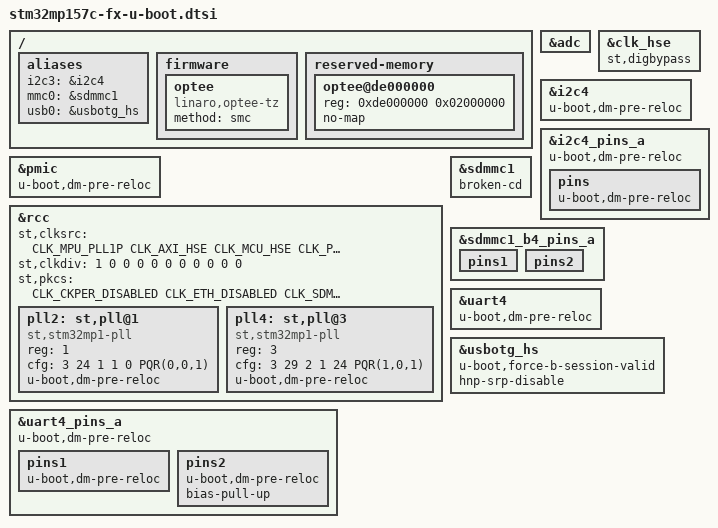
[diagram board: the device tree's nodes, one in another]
// SPDX-License-Identifier: GPL-2.0+ OR BSD-3-Clause
/*
 * Copyright : STMicroelectronics 2018
 */

#include <dt-bindings/clock/stm32mp1-clksrc.h>
#include "stm32mp15fx-u-boot.dtsi"
#include "stm32mp15-ddr3-1x4Gb-800.dtsi"

/ {
	aliases {
		i2c3 = &i2c4;
		mmc0 = &sdmmc1;
		usb0 = &usbotg_hs;
	};

	firmware {
		optee {
			compatible = "linaro,optee-tz";
			method = "smc";
		};
	};

	reserved-memory {
		optee@de000000 {
			reg = <0xde000000 0x02000000>;
			no-map;
		};
	};
};

&adc {
	status = "okay";
};

&clk_hse {
	st,digbypass;
};

&i2c4 {
	u-boot,dm-pre-reloc;
};

&i2c4_pins_a {
	u-boot,dm-pre-reloc;
	pins {
		u-boot,dm-pre-reloc;
	};
};

&pmic {
	u-boot,dm-pre-reloc;
};

&rcc {
	st,clksrc = <
		CLK_MPU_PLL1P
		CLK_AXI_HSE
		CLK_MCU_HSE
		CLK_PLL12_HSE
		CLK_PLL3_HSE
		CLK_PLL4_HSE
		CLK_RTC_LSE
		CLK_MCO1_DISABLED
		CLK_MCO2_DISABLED
	>;

	st,clkdiv = <
		1 /*MPU*/
		0 /*AXI*/
		0 /*MCU*/
		0 /*APB1*/
		0 /*APB2*/
		0 /*APB3*/
		0 /*APB4*/
		0 /*APB5*/
		0 /*RTC*/
		0 /*MCO1*/
		0 /*MCO2*/
	>;

	st,pkcs = <
		CLK_CKPER_DISABLED
		CLK_ETH_DISABLED
		CLK_SDMMC12_HCLK6
		CLK_STGEN_HSE
		CLK_USBPHY_PLL4R
		CLK_SPI2S1_PLL4P
		CLK_SPI2S23_DISABLED
		CLK_SPI45_DISABLED
		CLK_SPI6_DISABLED
		CLK_I2C46_PCLK5
		CLK_SDMMC3_DISABLED
		CLK_USBO_PLL4R
		CLK_ADC_PLL4R
		CLK_CEC_DISABLED
		CLK_I2C12_PCLK1
		CLK_I2C35_PCLK1
		CLK_UART1_PCLK5
		CLK_UART24_PCLK1
		CLK_UART35_PCLK1
		CLK_UART6_PCLK2
		CLK_UART78_PCLK1
		CLK_SPDIF_DISABLED
		CLK_SAI1_DISABLED
		CLK_SAI2_DISABLED
		CLK_SAI3_DISABLED
		CLK_SAI4_DISABLED
		CLK_RNG1_LSI
		CLK_RNG2_LSI
		CLK_LPTIM1_DISABLED
		CLK_LPTIM23_DISABLED
		CLK_LPTIM45_DISABLED
	>;

	pll2: st,pll@1 {
		compatible = "st,stm32mp1-pll";
		reg = <1>;
		cfg = < 3 24 1 1 0 PQR(0,0,1) >;
		u-boot,dm-pre-reloc;
	};

	pll4: st,pll@3 {
		compatible = "st,stm32mp1-pll";
		reg = <3>;
		cfg = < 3 29 2 1 24 PQR(1,0,1) >;
		u-boot,dm-pre-reloc;
	};
};

&sdmmc1 {
	u-boot,dm-spl;
	broken-cd;
	/delete-property/ cd-gpios;
};

&sdmmc1_b4_pins_a {
	u-boot,dm-spl;
	pins1 {
		u-boot,dm-spl;
	};
	pins2 {
		u-boot,dm-spl;
	};
};

&uart4 {
	u-boot,dm-pre-reloc;
};

&uart4_pins_a {
	u-boot,dm-pre-reloc;
	pins1 {
		u-boot,dm-pre-reloc;
	};
	pins2 {
		u-boot,dm-pre-reloc;
		/* pull-up on rx to avoid floating level */
		bias-pull-up;
	};
};

&usbotg_hs {
	u-boot,force-b-session-valid;
	hnp-srp-disable;
};
